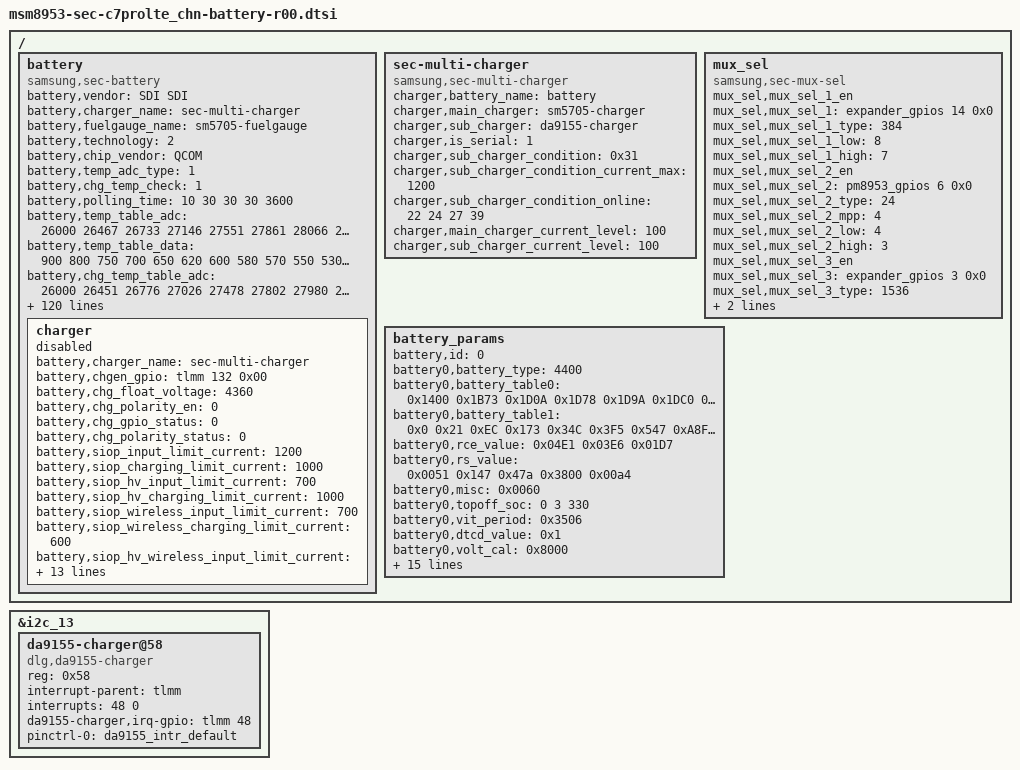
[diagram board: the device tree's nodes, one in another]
/* Copyright (c) 2014, The Linux Foundation. All rights reserved.
 *
 * This program is free software; you can redistribute it and/or modify
 * it under the terms of the GNU General Public License version 2 and
 * only version 2 as published by the Free Software Foundation.
 *
 * This program is distributed in the hope that it will be useful,
 * but WITHOUT ANY WARRANTY; without even the implied warranty of
 * MERCHANTABILITY or FITNESS FOR A PARTICULAR PURPOSE.  See the
 * GNU General Public License for more details.
 */

/ {
	battery {
		status = "okay";
		compatible = "samsung,sec-battery";
		battery,vendor = "SDI SDI";
		battery,charger_name = "sec-multi-charger";
		battery,fuelgauge_name = "sm5705-fuelgauge";
		battery,technology = <2>; /* POWER_SUPPLY_TECHNOLOGY_LION */

		battery,chip_vendor = "QCOM";
		battery,temp_adc_type = <1>; /* SEC_BATTERY_ADC_TYPE_AP */

		battery,chg_temp_check = <1>;

		battery,polling_time = <10 30 30 30 3600>;

		battery,temp_table_adc = <26000 26467 26733 27146 27551 27861 28066 28294 28403 28638 28908 29205 29328 29435 29751 30071 30857 31796 32750 33885 34962 36048 37109 37451 37627 37861 38097 38173 38265 38704 38928 39088 39391 39814 40005 40521 40993 41373>;

		battery,temp_table_data = <900 800 750 700 650 620 600 580 570 550 530 510 500 490 470 450 400 350 300 250 200 150 100 80 70 60 50 40 30 10 0 (-10) (-30) (-50) (-70) (-100) (-150) (-200)>;

		battery,chg_temp_table_adc = <26000 26451 26776 27026 27478 27802 27980 28225 28326 28574 28859 29123 29280 29434 29712 29995 30775 31674 32611 33611 34891 35973 37037 37328 37471 37748 38021 38091 38152 38537 38741 38922 39280 39500 39886 40402 40964 41455>;

		battery,chg_temp_table_data = <900 800 750 700 650 620 600 580 570 550 530 510 500 490 470 450 400 350 300 250 200 150 100 80 70 60 50 40 30 10 0 (-10) (-30) (-50) (-70) (-100) (-150) (-200)>;

		battery,siop_input_limit_current = <1200>;
		battery,siop_charging_limit_current = <1000>;
		battery,siop_hv_input_limit_current = <700>;
		battery,siop_hv_charging_limit_current = <1000>;

		battery,siop_wireless_input_limit_current = <700>;
		battery,siop_wireless_charging_limit_current = <600>;
		battery,siop_hv_wireless_input_limit_current = <500>;
		battery,siop_hv_wireless_charging_limit_current = <1000>;
		battery,siop_call_cv_current = <500>;
		battery,siop_call_cc_current = <500>;

		battery,input_current_limit = <1950 500 500 1950 475 900 1000 500 500 1000 820 1800 1800 500 1300 300 700 1300 1500 300 80 500 1650 1650 1650 1400 900 820 820 500 1000 1000 820 820 820 820 820 820 500 1950 500>;
		battery,fast_charging_current = <2100 0 500 2100 500 1200 1000 500 0 1200 1000 2100 2100 0 1300 300 700 1300 1500 300 80 0 2475 1000 2475 1400 1200 1000 1000 0 0 1000 1000 1000 1000 1000 1000 1000 0 2475 500>;
		battery,full_check_current_1st = <330 0 330 330 330 330 330 330 0 330 330 330 330 0 330 330 330 330 330 330 330 0 330 330 330 330 330 330 330 0 0 330 330 330 330 330 330 330 0 330 330>;
		battery,full_check_current_2nd = <150 0 150 150 150 150 150 150 0 150 150 150 150 0 150 150 150 150 150 150 150 0 150 150 150 150 150 150 150 0 0 150 150 150 150 150 150 150 0 150 150>;

		battery,step_charging_type = <0x5>;
		battery,step_charging_charge_power = <20000>;
		battery,step_charging_condtion = <4400>;
		battery,step_charging_current = <2475>; /* 0.75C */

		battery,adc_check_count = <5>;

		battery,cable_check_type = <4>; /* SEC_BATTERY_CABLE_CHECK_PSY */
		battery,cable_source_type = <3>; /* SEC_BATTERY_CABLE_SOURCE_EXTERNAL */
		battery,event_waiting_time = <600>;
		battery,polling_type = <1>; /* SEC_BATTERY_MONITOR_ALARM */
		battery,monitor_initial_count = <3>;

		battery,battery_check_type = <0>; /* SEC_BATTERY_CHECK_NONE */
		battery,check_count = <0>;
		battery,check_adc_max = <1440>;
		battery,check_adc_min = <0>;

		battery,ovp_uvlo_check_type = <3>; /* SEC_BATTERY_OVP_UVLO_CHGPOLLING */

		battery,thermal_source = <2>; /* SEC_BATTERY_THERMAL_SOURCE_ADC */
		battery,chg_thermal_source = <1>;

		battery,temp_check_type = <2>; /* SEC_BATTERY_TEMP_CHECK_TEMP */
		battery,temp_check_count = <1>;
		battery,temp_highlimit_threshold_event = <800>;
		battery,temp_highlimit_recovery_event = <750>;
		battery,temp_high_threshold_event = <500>;
		battery,temp_high_recovery_event = <450>;
		battery,temp_low_threshold_event = <(0)>;
		battery,temp_low_recovery_event = <50>;
		battery,temp_highlimit_threshold_normal = <800>;
		battery,temp_highlimit_recovery_normal = <750>;
		battery,temp_high_threshold_normal = <500>;
		battery,temp_high_recovery_normal = <450>;
		battery,temp_low_threshold_normal = <(0)>;
		battery,temp_low_recovery_normal = <50>;
		battery,temp_highlimit_threshold_lpm = <800>;
		battery,temp_highlimit_recovery_lpm = <750>;
		battery,temp_high_threshold_lpm = <500>;
		battery,temp_high_recovery_lpm = <450>;
		battery,temp_low_threshold_lpm = <(0)>;
		battery,temp_low_recovery_lpm = <50>;
		battery,full_check_type = <2>; /* SEC_BATTERY_FULLCHARGED_FG_CURRENT */
		battery,full_check_type_2nd = <2>; /* SEC_BATTERY_FULLCHARGED_FG_CURRENT */
		battery,full_check_count = <2>;
		battery,chg_gpio_full_check = <0>;
		battery,chg_polarity_full_check = <1>;
		
		battery,discharging_temp_alpha = <103>;
		battery,charging_temp_alpha = <95>;

		/* AFC 1.0 15W TA: 9V*1.67A / 5V*2A */
		battery,chg_high_temp = <452>;
		battery,chg_high_temp_recovery = <451>;
		battery,chg_charging_limit_current = <2300>;

		/* AFC 2.0 18W TA: 9v/8v/7v/6v/5v/ * 1.95A  */
		battery,chg_18w_high_temp = <438>;
		battery,chg_18w_high_temp_recovery = <436>;
		battery,chg_18w_high_temp_input_voltage = <9 8 7 6 6>; /* V */
		battery,chg_18w_high_temp_fast_charging_current = <3000 3000 3000 2800 2400>; /* mA */

		/* SEC_BATTERY_FULL_CONDITION_SOC |
		   SEC_BATTERY_FULL_CONDITION_NOTIMEFULL |
		   SEC_BATTERY_FULL_CONDITION_VCELL */
		battery,full_condition_type = <13>;
		battery,full_condition_soc = <93>;
		battery,full_condition_vcell = <4250>;

		battery,recharge_check_count = <1>;
		battery,recharge_condition_type = <4>; /* SEC_BATTERY_RECHARGE_CONDITION_VCELL */
		battery,recharge_condition_soc = <98>;
		battery,recharge_condition_vcell = <4300>;

		//battery,self_discharging_en;
		battery,self_discharging_type = <2>;	/* SEC_BAT_SELF_DISCHARGING_BY_CHG */
		//battery,factory_discharging = <&expander_gpios 13 0x00>;

		battery,force_discharging_limit = <600>;
		battery,force_discharging_recov = <550>;
		battery,self_discharging_voltage_limit = <4250>;
		battery,discharging_adc_max = <29864>;
		battery,discharging_adc_min = <25768>;
		battery,discharging_ntc_limit = <2750>;

		battery,charging_total_time = <21600>;
		battery,recharging_total_time = <5400>;
		battery,charging_reset_time = <0>;

		battery,swelling_high_temp_block = <450>;
		battery,swelling_high_temp_recov = <400>;
		battery,swelling_low_temp_block = <100>;
		battery,swelling_low_temp_recov = <150>;
		battery,swelling_low_temp_additional = <50>;
		//battery,swelling_chg_current = <1500>;
		battery,swelling_high_temp_current = <1188>;
		battery,swelling_low_temp_current = <1188>;
		battery,swelling_low_temp_additional_current = <594>;     /* 0.18C */
		battery,swelling_low_temp_topoff = <165>;
		battery,swelling_high_temp_topoff = <165>;
		battery,swelling_drop_float_voltage = <4150>;
		battery,swelling_high_rechg_voltage = <4100>;
		battery,swelling_low_rechg_voltage = <4000>;
		battery,swelling_offset_voltage = <20>;
		battery,swelling_block_time = <600>;

		battery,self_discharging_temp_block = <550>;
		battery,self_discharging_volt_block = <4250>;
		battery,self_discharging_temp_recov = <500>;
		battery,self_discharging_temp_pollingtime = <400>;

		battery,hv_overheat_check = <1>;
		battery,hv_overheat_batt_temp_block = <420>;
		battery,hv_overheat_chg_temp_block = <500>;
		battery,hv_overheat_batt_temp_recov = <390>;
		battery,hv_overheat_input_current_limit = <100>;

		battery,chg_float_voltage = <4360>;

		qcom,sec-battery-vadc = <&pm8953_vadc>;


		charger {
			status = "disable";
			/* Charger */
			battery,charger_name = "sec-multi-charger";
			battery,chgen_gpio = <&tlmm 132 0x00>;
			battery,chg_float_voltage = <4360>;

			battery,chg_polarity_en = <0>;
			battery,chg_gpio_status = <0>;
			battery,chg_polarity_status = <0>;

			battery,siop_input_limit_current = <1200>;
			battery,siop_charging_limit_current = <1000>;
			battery,siop_hv_input_limit_current = <700>;
			battery,siop_hv_charging_limit_current = <1000>;

			battery,siop_wireless_input_limit_current = <700>;
			battery,siop_wireless_charging_limit_current = <600>;
			battery,siop_hv_wireless_input_limit_current = <500>;
			battery,siop_hv_wireless_charging_limit_current = <1000>;
			battery,siop_call_cv_current = <500>;
			battery,siop_call_cc_current = <500>;

			battery,input_current_limit = <1950 500 500 1950 475 900 1000 500 500 1000 820 1800 1800 500 1300 300 700 1300 1500 300 80 500 1650 1650 1650 1400 900 820 820 500 1000 1000 820 820 820 820 820 820 500 1950 500>;
			battery,fast_charging_current = <2100 0 500 2100 500 1200 1000 500 0 1200 1000 2100 2100 0 1300 300 700 1300 1500 300 80 0 2475 1000 2475 1400 1200 1000 1000 0 0 1000 1000 1000 1000 1000 1000 1000 0 2475 500>;
			battery,full_check_current_1st = <330 0 330 330 330 330 330 330 0 330 330 330 330 0 330 330 330 330 330 330 330 0 330 330 330 330 330 330 330 0 0 330 330 330 330 330 330 330 0 330 330>;
			battery,full_check_current_2nd = <150 0 150 150 150 150 150 150 0 150 150 150 150 0 150 150 150 150 150 150 150 0 150 150 150 150 150 150 150 0 0 150 150 150 150 150 150 150 0 150 150>;
		};
	};

	sec-multi-charger {
		status = "okay";
		compatible = "samsung,sec-multi-charger";

		charger,battery_name = "battery";
		charger,main_charger = "sm5705-charger";
		charger,sub_charger = "da9155-charger";

		charger,is_serial = <1>;

		charger,sub_charger_condition = <0x31>;
		charger,sub_charger_condition_current_max = <1200>;
		charger,sub_charger_condition_online = <22 24 27 39>;

		charger,main_charger_current_level = <100>; /* main:sub=100:100=5:5 */
		charger,sub_charger_current_level = <100>;
	};

	mux_sel {
		compatible = "samsung,sec-mux-sel";
		mux_sel,mux_sel_1_en;
		mux_sel,mux_sel_1 = <&expander_gpios 14 0x0>;
		mux_sel,mux_sel_1_type = <384>; /* SEC_MUX_SEL_EAR_MIC_TYPEC | SEC_MUX_SEL_EAR_MIC_35MM */
		// mux_sel,mux_sel_1_mpp = <2>; /* SEC_MPP2_MUX_SEL */
		mux_sel,mux_sel_1_low = <8>; /* SEC_MUX_SEL_EAR_MIC_35MM */
		mux_sel,mux_sel_1_high = <7>; /* SEC_MUX_SEL_EAR_MIC_TYPEC */

		mux_sel,mux_sel_2_en;
		mux_sel,mux_sel_2 = <&pm8953_gpios 6 0x0>;
		mux_sel,mux_sel_2_type = <24>; /* CHG_THM_MUX_SEL | AP_THM_MUX_SEL */
		mux_sel,mux_sel_2_mpp = <4>; /* SEC_MPP4_MUX_SEL */
		mux_sel,mux_sel_2_low = <4>; /* SEC_MUX_SEL_AP_THM */
		mux_sel,mux_sel_2_high = <3>; /* SEC_MUX_SEL_CHG_THM */	

		mux_sel,mux_sel_3_en;
		mux_sel,mux_sel_3 = <&expander_gpios 3 0x0>;
		mux_sel,mux_sel_3_type = <1536>; /* SEC_MUX_SEL_EAR_OUT_TYPEC | SEC_MUX_SEL_EAR_OUT_35MM */
		//mux_sel,mux_sel_3_mpp = <2>; /* SEC_MPP2_MUX_SEL */
		mux_sel,mux_sel_3_low = <10>; /* SEC_MUX_SEL_EAR_OUT_35MM */
		mux_sel,mux_sel_3_high = <9>; /*SEC_MUX_SEL_EAR_OUT_TYPEC */		
	};

	battery_params {
		battery,id = <0>; /* -1 means auto, detected by F/G */
		battery0,battery_type = <4400>; /* 4200 4350 4400 */
		battery0,battery_table0 = <0x1400 0x1B73 0x1D0A 0x1D78 0x1D9A 0x1DC0 0x1DF7 0x1E75 0x1EC9 0x1F0B 0x1F7C 0x1FF2 0x20EE 0x21CE 0x22C3 0x2400>;
		battery0,battery_table1 = <0x0 0x21 0xEC 0x173 0x34C 0x3F5 0x547 0xA8F 0xD33 0xE85 0xFD7 0x11D1 0x151E 0x17C2 0x1A66 0x1A6D>;
		battery0,rce_value = <0x04E1 0x03E6 0x01D7>;
		battery0,rs_value = <0x0051 0x147 0x47a 0x3800 0x00a4>; /*rs p_mix_factor n_mix_factor max min*/
		battery0,misc = <0x0060>;
		battery0,topoff_soc = <0 3 330>; /*enable soc current*/
		battery0,vit_period = <0x3506>;
		battery0,dtcd_value = <0x1>;
		battery0,volt_cal = <0x8000>;
		battery0,curr_offset = <1 0x0000>; /*en_auto offset*/
		battery0,p_curr_cal = <0x009A>;
		battery0,n_curr_cal = <0x0068>;
		battery0,mix_value = <0x0503 0x0004>; /*mix_rate init_blank*/
		battery0,temp_std = <25>;
		battery0,temp_cal = <1 6 1 11 (-1) 1 6 1 9 1>; /* en_h, p_de, p_fa, n_de, n_fa, en_l, p_de, p_fa, n_de, n_fa, */
		battery0,ext_temp_cal = <0 2 1 2 1 1 2 3 2 3>; /* en_h, p_de, p_fa, n_de, n_fa, en_l, p_de, p_fa, n_de, n_fa, */
		battery0,temp_volcal = <1 15 1>; /* en, temp, cal */
		battery0,temp_offset = <1 11 1 1 8 (-1)>; /* en_high level offset en_low level offset */
		battery0,cycle_cfg = <7 1 3>; /*high_limit low_limit cntl*/
		battery0,curr_lcal = <0 0x8888 0x8888 0x8888>;
		battery0,tem_poff = <3400 50 3300 50>;
		battery0,v_offset_cancel = <1 0 100 10>; /* en_p, en_n, level, mohm */
		battery0,v_alarm = <3200>;
		battery0,full_offset = <20 4>; /*margin extra_offset*/
	};
};

	&i2c_13 {
		da9155-charger@58 {
			status = "okay";
			compatible = "dlg,da9155-charger";
			reg = <0x58>;
			interrupt-parent = <&tlmm>;
			interrupts = <48 0>;
			da9155-charger,irq-gpio = <&tlmm 48 0x0>;
			pinctrl-names = "default";
			pinctrl-0 = <&da9155_intr_default>;
		};
	};


